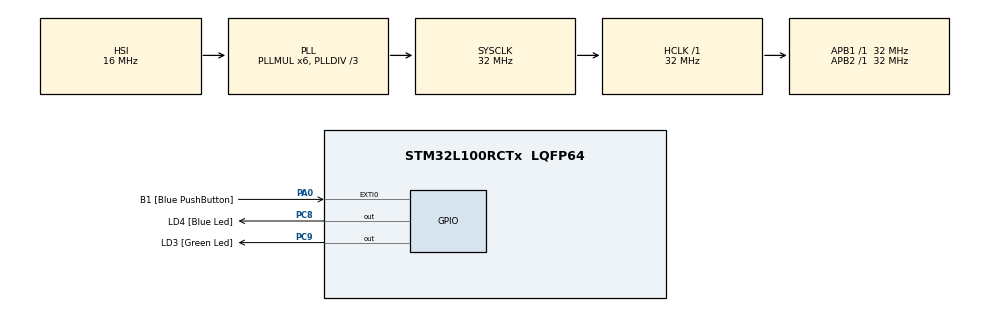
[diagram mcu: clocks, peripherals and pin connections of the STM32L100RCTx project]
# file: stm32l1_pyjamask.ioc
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Mcu.Family=STM32L1
Mcu.Name=STM32L100RCTx
Mcu.Package=LQFP64
NVIC.PriorityGroup=NVIC_PRIORITYGROUP_0
PA0-WKUP1.GPIO_Label=B1 [Blue PushButton]
PA0-WKUP1.GPIO_ModeDefaultEXTI=GPIO_MODE_EVT_RISING
PA0-WKUP1.Signal=GPXTI0
PA13.GPIO_Label=SWDIO
PA13.Mode=Serial_Wire
PA13.Signal=SYS_JTMS-SWDIO
PA14.GPIO_Label=SWCLK
PA14.Mode=Serial_Wire
PA14.Signal=SYS_JTCK-SWCLK
PB3.GPIO_Label=SWO
PB3.Signal=SYS_JTDO-TRACESWO
PC14-OSC32_IN.GPIO_Label=PC14-OSC32_IN
PC14-OSC32_IN.Signal=RCC_OSC32_IN
PC15-OSC32_OUT.GPIO_Label=PC15-OSC32_OUT
PC15-OSC32_OUT.Signal=RCC_OSC32_OUT
PC8.GPIO_Label=LD4 [Blue Led]
PC8.Signal=GPIO_Output
PC9.GPIO_Label=LD3 [Green Led]
PC9.Signal=GPIO_Output
PH0-OSC_IN.GPIO_Label=PH0-OSC_IN
PH0-OSC_IN.Mode=HSE-External-Clock-Source
PH0-OSC_IN.Signal=RCC_OSC_IN
PH1-OSC_OUT.GPIO_Label=PH1-OSC_OUT
PH1-OSC_OUT.Signal=RCC_OSC_OUT
ProjectManager.HeapSize=0x200
ProjectManager.StackSize=0x400
ProjectManager.TargetToolchain=Makefile
RCC.48MHZClocksFreq_Value=48000000
RCC.AHBFreq_Value=32000000
RCC.APB1Freq_Value=32000000
RCC.APB1TimFreq_Value=32000000
RCC.APB2Freq_Value=32000000
RCC.APB2TimFreq_Value=32000000
RCC.HCLKFreq_Value=32000000
RCC.HSE_VALUE=8000000
RCC.HSI_VALUE=16000000
RCC.LSEState=RCC_LSE_ON
RCC.LSE_VALUE=32768
RCC.MSI_VALUE=2097000
RCC.PLLDIV=RCC_PLL_DIV3
RCC.PLLMUL=RCC_PLL_MUL6
RCC.RTCClockSelectionVirtual=RCC_RTCCLKSOURCE_LSE
RCC.SYSCLKFreq_VALUE=32000000
RCC.SYSCLKSource=RCC_SYSCLKSOURCE_PLLCLK
RCC.USBOutput=48000000
RCC.VCOOutputFreq_Value=96000000
board=STM32L100C-DISCO

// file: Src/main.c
/* USER CODE BEGIN Header */
/**
  ******************************************************************************
  * @file           : main.c
  * @brief          : Main program body
  ******************************************************************************
  * @attention
  *
  * Copyright (c) 2023 STMicroelectronics.
  * All rights reserved.
  *
  * This software is licensed under terms that can be found in the LICENSE file
  * in the root directory of this software component.
  * If no LICENSE file comes with this software, it is provided AS-IS.
  *
  ******************************************************************************
  */
/* USER CODE END Header */
#include "main.h"
#include "gpio.h"
#include "STD.h"

/* USER CODE BEGIN PV */

extern uint32_t bench_speed1();
extern uint32_t bench_speed2();
extern uint32_t bench_speed3();
extern uint32_t bench_speed4();

//static unsigned long get_cycle_count();

unsigned long bench_times[] = {-1, -1, -1, -1};

/* USER CODE END PV */

void SystemClock_Config(void);

int main(void)
{

  /* MCU Configuration--------------------------------------------------------*/

  /* Reset of all peripherals, Initializes the Flash interface and the Systick. */
  HAL_Init();

  /* Configure the system clock */
  SystemClock_Config();

  /* USER CODE BEGIN SysInit */
for (int i = 0; i < 1; i++){

    int len1 = bench_speed1();
    bench_times[0] = len1;
    int len2 = bench_speed2();
    bench_times[1] = len2;
    int len3 = bench_speed3();
    bench_times[2] = len3;
    int len4 = bench_speed4();
    bench_times[3] = len4;
  }

  /* USER CODE END SysInit */

  /* Initialize all configured peripherals */
  MX_GPIO_Init();

  /* Infinite loop */
  while (1)
  {

  }
}

void SystemClock_Config(void)
{
  RCC_OscInitTypeDef RCC_OscInitStruct = {0};
  RCC_ClkInitTypeDef RCC_ClkInitStruct = {0};

  /** Configure the main internal regulator output voltage
  */
  __HAL_PWR_VOLTAGESCALING_CONFIG(PWR_REGULATOR_VOLTAGE_SCALE1);

  /** Initializes the RCC Oscillators according to the specified parameters
  * in the RCC_OscInitTypeDef structure.
  */
  RCC_OscInitStruct.OscillatorType = RCC_OSCILLATORTYPE_HSI;
  RCC_OscInitStruct.HSIState = RCC_HSI_ON;
  RCC_OscInitStruct.HSICalibrationValue = RCC_HSICALIBRATION_DEFAULT;
  RCC_OscInitStruct.PLL.PLLState = RCC_PLL_ON;
  RCC_OscInitStruct.PLL.PLLSource = RCC_PLLSOURCE_HSI;
  RCC_OscInitStruct.PLL.PLLMUL = RCC_PLL_MUL6;
  RCC_OscInitStruct.PLL.PLLDIV = RCC_PLL_DIV3;
  if (HAL_RCC_OscConfig(&RCC_OscInitStruct) != HAL_OK)
  {
    Error_Handler();
  }

  /** Initializes the CPU, AHB and APB buses clocks
  */
  RCC_ClkInitStruct.ClockType = RCC_CLOCKTYPE_HCLK|RCC_CLOCKTYPE_SYSCLK
                              |RCC_CLOCKTYPE_PCLK1|RCC_CLOCKTYPE_PCLK2;
  RCC_ClkInitStruct.SYSCLKSource = RCC_SYSCLKSOURCE_PLLCLK;
  RCC_ClkInitStruct.AHBCLKDivider = RCC_SYSCLK_DIV1;
  RCC_ClkInitStruct.APB1CLKDivider = RCC_HCLK_DIV1;
  RCC_ClkInitStruct.APB2CLKDivider = RCC_HCLK_DIV1;

  if (HAL_RCC_ClockConfig(&RCC_ClkInitStruct, FLASH_LATENCY_1) != HAL_OK)
  {
    Error_Handler();
  }
}

void Error_Handler(void)
{
  __disable_irq();
  while (1)
  {
  }
}

static unsigned long get_cycle_count()
{
   /* retrieve the CPU cycles using the Cortex-M DWT->CYCCNT register
    * avaialable only starting from CM3
    */

#if (__CORTEX_M >= 0x03U)
    static int dwt_started = 0;
    if( dwt_started == 0 )
    {
      dwt_started = 1;
      /* Enable Tracing */
        CoreDebug->DEMCR |= CoreDebug_DEMCR_TRCENA_Msk;
#if (__CORTEX_M == 0x07U)
        /* in Cortex M7, the trace needs to be unlocked
         * via the DWT->LAR register with 0xC5ACCE55 value
         */
        DWT->LAR = 0xC5ACCE55;
#endif
        DWT->CTRL |= DWT_CTRL_CYCCNTENA_Msk;

      /* Reset counter */
      DWT->CYCCNT = 0;
    }

    return (unsigned long)DWT->CYCCNT;
#else
    return 0;
#endif
}
